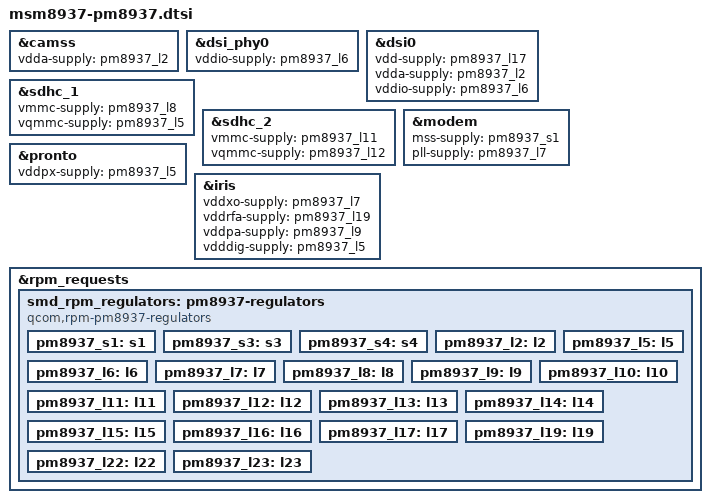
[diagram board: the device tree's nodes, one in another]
// SPDX-License-Identifier: GPL-2.0-only
// Copyright (c) 2020, The Linux Foundation. All rights reserved.

#include "msm8937.dtsi"
#include "pm8937.dtsi"
/*
&hsusb_phy {
	phy-supply = <&pm8937_l3>;
	vdda-pll-supply = <&pm8937_l7>;
	vdda-phy-dpdm-supply = <&pm8937_l13>;
};
*/
&camss {
	vdda-supply = <&pm8937_l2>;
};

&dsi_phy0 {
	vddio-supply = <&pm8937_l6>;
	//vdda-supply = <&pm8937_l2>; 
};

&dsi0 {
	vdd-supply = <&pm8937_l17>;
	vdda-supply = <&pm8937_l2>;
	vddio-supply = <&pm8937_l6>;
};

&sdhc_1 {
	vmmc-supply = <&pm8937_l8>;
	vqmmc-supply = <&pm8937_l5>;
};

&sdhc_2 {
	vmmc-supply = <&pm8937_l11>;
	vqmmc-supply = <&pm8937_l12>;
};

&modem {
	mss-supply = <&pm8937_s1>;
	pll-supply = <&pm8937_l7>;
};

&pronto {
	vddpx-supply = <&pm8937_l5>;
};

&iris {
	vddxo-supply = <&pm8937_l7>;
	vddrfa-supply = <&pm8937_l19>;
	vddpa-supply = <&pm8937_l9>;
	vdddig-supply = <&pm8937_l5>;
};
/*
&cpr {
	vdd-apc-supply = <&vreg_apc>;
	vdd-apc-step-uv = <5000>;
};
*/
&rpm_requests {
	smd_rpm_regulators: pm8937-regulators {
		compatible = "qcom,rpm-pm8937-regulators";

		pm8937_s1: s1 {};
		pm8937_s3: s3 {};
		pm8937_s4: s4 {};
		pm8937_l2: l2 {};
	
		pm8937_l5: l5 {};
		pm8937_l6: l6 {};
		pm8937_l7: l7 {};
		pm8937_l8: l8 {};
		pm8937_l9: l9 {};
		pm8937_l10: l10 {};
		pm8937_l11: l11 {};
		pm8937_l12: l12 {};
		pm8937_l13: l13 {};
		pm8937_l14: l14 {};
		pm8937_l15: l15 {};
		pm8937_l16: l16 {};
		pm8937_l17: l17 {};
		pm8937_l19: l19 {};
		pm8937_l22: l22 {};
		pm8937_l23: l23 {};
	};
};
